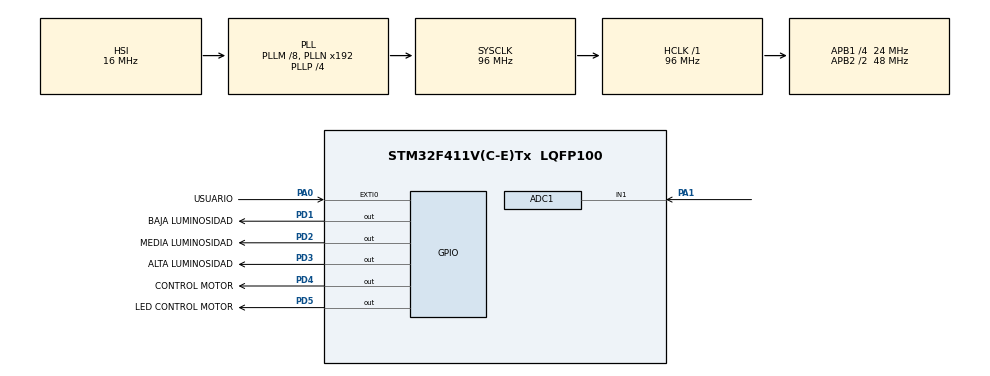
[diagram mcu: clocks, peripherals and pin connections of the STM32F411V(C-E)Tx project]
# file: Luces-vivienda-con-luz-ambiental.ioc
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ADC1.Channel-1\#ChannelRegularConversion=ADC_CHANNEL_1
ADC1.NbrOfConversionFlag=1
ADC1.Rank-1\#ChannelRegularConversion=1
ADC1.Resolution=ADC_RESOLUTION_8B
ADC1.SamplingTime-1\#ChannelRegularConversion=ADC_SAMPLETIME_3CYCLES
ADC1.master=1
Mcu.Family=STM32F4
Mcu.Name=STM32F411V(C-E)Tx
Mcu.Package=LQFP100
NVIC.EXTI0_IRQn=true\:0\:0\:false\:false\:true\:true\:true
NVIC.PriorityGroup=NVIC_PRIORITYGROUP_0
NVIC.TIM1_UP_TIM10_IRQn=true\:0\:0\:false\:false\:true\:false\:true
NVIC.TimeBase=TIM1_UP_TIM10_IRQn
NVIC.TimeBaseIP=TIM1
PA0-WKUP.GPIO_Label=USUARIO
PA0-WKUP.Signal=GPXTI0
PA1.Signal=ADCx_IN1
PD1.GPIO_Label=BAJA LUMINOSIDAD
PD1.Signal=GPIO_Output
PD2.GPIO_Label=MEDIA LUMINOSIDAD
PD2.Signal=GPIO_Output
PD3.GPIO_Label=ALTA LUMINOSIDAD
PD3.Signal=GPIO_Output
PD4.GPIO_Label=CONTROL MOTOR
PD4.PinState=GPIO_PIN_SET
PD4.Signal=GPIO_Output
PD5.GPIO_Label=LED CONTROL MOTOR
PD5.Signal=GPIO_Output
ProjectManager.HeapSize=0x200
ProjectManager.StackSize=0x400
ProjectManager.TargetToolchain=STM32CubeIDE
RCC.48MHZClocksFreq_Value=48000000
RCC.AHBFreq_Value=96000000
RCC.APB1CLKDivider=RCC_HCLK_DIV4
RCC.APB1Freq_Value=24000000
RCC.APB1TimFreq_Value=48000000
RCC.APB2CLKDivider=RCC_HCLK_DIV2
RCC.APB2Freq_Value=48000000
RCC.APB2TimFreq_Value=96000000
RCC.CortexFreq_Value=96000000
RCC.HCLKFreq_Value=96000000
RCC.HSE_VALUE=8000000
RCC.HSI_VALUE=16000000
RCC.LSE_VALUE=32768
RCC.PLLI2SM=5
RCC.PLLI2SN=200
RCC.PLLM=8
RCC.PLLP=RCC_PLLP_DIV4
RCC.PLLQ=8
RCC.SYSCLKFreq_VALUE=96000000
RCC.SYSCLKSource=RCC_SYSCLKSOURCE_PLLCLK
RCC.VCOOutputFreq_Value=384000000
SH.ADCx_IN1.0=ADC1_IN1,IN1
VP_SYS_VS_tim1.Mode=TIM1
VP_TIM10_VS_ClockSourceINT.Mode=Enable_Timer
board=STM32F411E-DISCO

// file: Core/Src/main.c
/* USER CODE BEGIN Header */
/**
  ******************************************************************************
  * @file           : main.c
  * @brief          : Main program body
  ******************************************************************************
  * @attention
  *
  * <h2><center>&copy; Copyright (c) 2021 STMicroelectronics.
  * All rights reserved.</center></h2>
  *
  * This software component is licensed by ST under BSD 3-Clause license,
  * the "License"; You may not use this file except in compliance with the
  * License. You may obtain a copy of the License at:
  *                        opensource.org/licenses/BSD-3-Clause
  *
  ******************************************************************************
  */
/* USER CODE END Header */
#include "main.h"

volatile int flag = 0;

ADC_HandleTypeDef hadc1;

TIM_HandleTypeDef htim10;

void SystemClock_Config(void);
static void MX_GPIO_Init(void);
static void MX_ADC1_Init(void);
static void MX_TIM10_Init(void);
/* USER CODE BEGIN PFP */
void HAL_GPIO_EXTI_Callback(uint16_t GPIO_Pin){
	flag=1;
}
/* USER CODE END PFP */

/* USER CODE BEGIN 0 */
uint8_t LDR_valor;

uint8_t HIGH = 150;

uint8_t LOW = 30;
/* USER CODE END 0 */

int main(void)
{

  /* MCU Configuration--------------------------------------------------------*/

  /* Reset of all peripherals, Initializes the Flash interface and the Systick. */
  HAL_Init();

  /* Configure the system clock */
  SystemClock_Config();

  /* Initialize all configured peripherals */
  MX_GPIO_Init();
  MX_ADC1_Init();
  MX_TIM10_Init();
  /* USER CODE BEGIN 2 */
  HAL_TIM_Base_Start_IT(&htim10);
  /* USER CODE END 2 */

  /* Infinite loop */
  while (1)
  {
	  	  HAL_GPIO_WritePin(GPIOD, GPIO_PIN_1, GPIO_PIN_RESET);
	 	  HAL_GPIO_WritePin(GPIOD, GPIO_PIN_2, GPIO_PIN_RESET);
	 	  HAL_GPIO_WritePin(GPIOD, GPIO_PIN_3, GPIO_PIN_RESET);
	 	  while(!flag){
	 		  	  //ESTADO DE ESPERA PARA QUE EL USUARIO QUIERA REALIZAR LA MEDICIÓN
	 		  	HAL_GPIO_WritePin(GPIOD, GPIO_PIN_1, GPIO_PIN_SET);
	 		  	HAL_Delay(1500);
	 		    HAL_GPIO_WritePin(GPIOD, GPIO_PIN_2, GPIO_PIN_SET);
	 		    HAL_Delay(1500);
	 		    HAL_GPIO_WritePin(GPIOD, GPIO_PIN_3, GPIO_PIN_SET);
	 		    HAL_Delay(500);

	 		    HAL_GPIO_WritePin(GPIOD, GPIO_PIN_1, GPIO_PIN_RESET);
	 		    HAL_Delay(1500);
	 		    HAL_GPIO_WritePin(GPIOD, GPIO_PIN_2, GPIO_PIN_RESET);
	 		    HAL_Delay(1500);
	 		    HAL_GPIO_WritePin(GPIOD, GPIO_PIN_3, GPIO_PIN_RESET);

	 	  }
	 	  while(flag){//EL USUARIO AL PULSAR EL PA0, OBTINE UNA LUZ CORRESPONDIENTE A LA ILUMINACIÓN AMBENTE
	 		  HAL_ADC_Start(&hadc1);
	 		  //Se usa polling, se pasa el puntero y el tiempo
	 		  if(HAL_ADC_PollForConversion(&hadc1, 5)==HAL_OK){
	 			  LDR_valor=HAL_ADC_GetValue(&hadc1);
	 		  }
	 		  if(LDR_valor<LOW){
	 			HAL_GPIO_WritePin(GPIOD, GPIO_PIN_1, GPIO_PIN_SET);
	 			HAL_GPIO_WritePin(GPIOD, GPIO_PIN_4, GPIO_PIN_SET);
	 			HAL_GPIO_WritePin(GPIOD, GPIO_PIN_5, GPIO_PIN_SET);
	 		  }
	 		  else if (LDR_valor<HIGH)
	 			  HAL_GPIO_WritePin(GPIOD, GPIO_PIN_2, GPIO_PIN_SET);
	 		  else	{
	 			HAL_GPIO_WritePin(GPIOD, GPIO_PIN_3, GPIO_PIN_SET);
	 			HAL_GPIO_WritePin(GPIOD, GPIO_PIN_4, GPIO_PIN_RESET);
	 			HAL_GPIO_WritePin(GPIOD, GPIO_PIN_5, GPIO_PIN_RESET);
	 		  }
	 		  HAL_ADC_Stop(&hadc1);
	 		  HAL_Delay(5000);//Aquí se podría hacer el TEMPORIZADOR
	 		  HAL_GPIO_WritePin(GPIOD, GPIO_PIN_1, GPIO_PIN_RESET);
	 		  HAL_GPIO_WritePin(GPIOD, GPIO_PIN_2, GPIO_PIN_RESET);
	 		  HAL_GPIO_WritePin(GPIOD, GPIO_PIN_3, GPIO_PIN_RESET);
	 		  HAL_GPIO_WritePin(GPIOD, GPIO_PIN_4, GPIO_PIN_RESET);
	 		  HAL_GPIO_WritePin(GPIOD, GPIO_PIN_5, GPIO_PIN_RESET);
	 		  flag=0;
	 	  }

  }
}

void SystemClock_Config(void)
{
  RCC_OscInitTypeDef RCC_OscInitStruct = {0};
  RCC_ClkInitTypeDef RCC_ClkInitStruct = {0};

  /** Configure the main internal regulator output voltage
  */
  __HAL_RCC_PWR_CLK_ENABLE();
  __HAL_PWR_VOLTAGESCALING_CONFIG(PWR_REGULATOR_VOLTAGE_SCALE1);
  /** Initializes the RCC Oscillators according to the specified parameters
  * in the RCC_OscInitTypeDef structure.
  */
  RCC_OscInitStruct.OscillatorType = RCC_OSCILLATORTYPE_HSI;
  RCC_OscInitStruct.HSIState = RCC_HSI_ON;
  RCC_OscInitStruct.HSICalibrationValue = RCC_HSICALIBRATION_DEFAULT;
  RCC_OscInitStruct.PLL.PLLState = RCC_PLL_ON;
  RCC_OscInitStruct.PLL.PLLSource = RCC_PLLSOURCE_HSI;
  RCC_OscInitStruct.PLL.PLLM = 8;
  RCC_OscInitStruct.PLL.PLLN = 192;
  RCC_OscInitStruct.PLL.PLLP = RCC_PLLP_DIV4;
  RCC_OscInitStruct.PLL.PLLQ = 8;
  if (HAL_RCC_OscConfig(&RCC_OscInitStruct) != HAL_OK)
  {
    Error_Handler();
  }
  /** Initializes the CPU, AHB and APB buses clocks
  */
  RCC_ClkInitStruct.ClockType = RCC_CLOCKTYPE_HCLK|RCC_CLOCKTYPE_SYSCLK
                              |RCC_CLOCKTYPE_PCLK1|RCC_CLOCKTYPE_PCLK2;
  RCC_ClkInitStruct.SYSCLKSource = RCC_SYSCLKSOURCE_PLLCLK;
  RCC_ClkInitStruct.AHBCLKDivider = RCC_SYSCLK_DIV1;
  RCC_ClkInitStruct.APB1CLKDivider = RCC_HCLK_DIV4;
  RCC_ClkInitStruct.APB2CLKDivider = RCC_HCLK_DIV2;

  if (HAL_RCC_ClockConfig(&RCC_ClkInitStruct, FLASH_LATENCY_3) != HAL_OK)
  {
    Error_Handler();
  }
}

static void MX_ADC1_Init(void)
{

  ADC_ChannelConfTypeDef sConfig = {0};

  /** Configure the global features of the ADC (Clock, Resolution, Data Alignment and number of conversion)
  */
  hadc1.Instance = ADC1;
  hadc1.Init.ClockPrescaler = ADC_CLOCK_SYNC_PCLK_DIV2;
  hadc1.Init.Resolution = ADC_RESOLUTION_8B;
  hadc1.Init.ScanConvMode = DISABLE;
  hadc1.Init.ContinuousConvMode = DISABLE;
  hadc1.Init.DiscontinuousConvMode = DISABLE;
  hadc1.Init.ExternalTrigConvEdge = ADC_EXTERNALTRIGCONVEDGE_NONE;
  hadc1.Init.ExternalTrigConv = ADC_SOFTWARE_START;
  hadc1.Init.DataAlign = ADC_DATAALIGN_RIGHT;
  hadc1.Init.NbrOfConversion = 1;
  hadc1.Init.DMAContinuousRequests = DISABLE;
  hadc1.Init.EOCSelection = ADC_EOC_SINGLE_CONV;
  if (HAL_ADC_Init(&hadc1) != HAL_OK)
  {
    Error_Handler();
  }
  /** Configure for the selected ADC regular channel its corresponding rank in the sequencer and its sample time.
  */
  sConfig.Channel = ADC_CHANNEL_1;
  sConfig.Rank = 1;
  sConfig.SamplingTime = ADC_SAMPLETIME_3CYCLES;
  if (HAL_ADC_ConfigChannel(&hadc1, &sConfig) != HAL_OK)
  {
    Error_Handler();
  }

}

static void MX_TIM10_Init(void)
{

  htim10.Instance = TIM10;
  htim10.Init.Prescaler = 0;
  htim10.Init.CounterMode = TIM_COUNTERMODE_UP;
  htim10.Init.Period = 65535;
  htim10.Init.ClockDivision = TIM_CLOCKDIVISION_DIV1;
  htim10.Init.AutoReloadPreload = TIM_AUTORELOAD_PRELOAD_DISABLE;
  if (HAL_TIM_Base_Init(&htim10) != HAL_OK)
  {
    Error_Handler();
  }

}

static void MX_GPIO_Init(void)
{
  GPIO_InitTypeDef GPIO_InitStruct = {0};

  /* GPIO Ports Clock Enable */
  __HAL_RCC_GPIOA_CLK_ENABLE();
  __HAL_RCC_GPIOD_CLK_ENABLE();

  /*Configure GPIO pin Output Level */
  HAL_GPIO_WritePin(GPIOD, GPIO_PIN_1|GPIO_PIN_2|GPIO_PIN_3|GPIO_PIN_4
                          |GPIO_PIN_5, GPIO_PIN_RESET);

  /*Configure GPIO pin : PA0 */
  GPIO_InitStruct.Pin = GPIO_PIN_0;
  GPIO_InitStruct.Mode = GPIO_MODE_IT_RISING;
  GPIO_InitStruct.Pull = GPIO_NOPULL;
  HAL_GPIO_Init(GPIOA, &GPIO_InitStruct);

  /*Configure GPIO pins : PD1 PD2 PD3 PD4
                           PD5 */
  GPIO_InitStruct.Pin = GPIO_PIN_1|GPIO_PIN_2|GPIO_PIN_3|GPIO_PIN_4
                          |GPIO_PIN_5;
  GPIO_InitStruct.Mode = GPIO_MODE_OUTPUT_PP;
  GPIO_InitStruct.Pull = GPIO_NOPULL;
  GPIO_InitStruct.Speed = GPIO_SPEED_FREQ_LOW;
  HAL_GPIO_Init(GPIOD, &GPIO_InitStruct);

  /* EXTI interrupt init*/
  HAL_NVIC_SetPriority(EXTI0_IRQn, 0, 0);
  HAL_NVIC_EnableIRQ(EXTI0_IRQn);

}

void HAL_TIM_PeriodElapsedCallback(TIM_HandleTypeDef *htim)
{
  if (htim->Instance == TIM1) {
    HAL_IncTick();
  }
}

void Error_Handler(void)
{
  __disable_irq();
  while (1)
  {
  }
}

/************************ (C) COPYRIGHT STMicroelectronics *****END OF FILE****/
